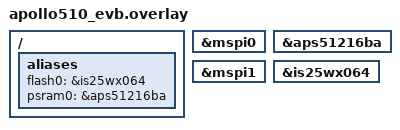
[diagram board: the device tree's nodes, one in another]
/*
 * Copyright (c) 2025, Ambiq Micro Inc. <www.ambiq.com>
 *
 * SPDX-License-Identifier: Apache-2.0
 */

/ {
	aliases {
		flash0 = &is25wx064;
		psram0 = &aps51216ba;
	};
};

&mspi0 {
	/delete-property/ zephyr,pm-device-runtime-auto;
	status = "okay";
};

&aps51216ba {
	/delete-property/ zephyr,pm-device-runtime-auto;
	status = "okay";
};

&mspi1 {
	/delete-property/ zephyr,pm-device-runtime-auto;
	status = "okay";
};

&is25wx064 {
	status = "okay";
};
